# STM32H7B0xxQ register map
File version: 1.0
Registers are 32-bit, read-write, reset 0x0 unless marked. A register's access mark holds for its fields unless they carry their own. Offsets are from the block's base; [hi:lo] are bit positions; {n}, {i} and the like mark numbered series; 'fields as' and 'values as' point back to an identical list.

## OTFDEC1
Base 0x5200B800
Same registers: OTFDEC2 0x5200BC00
0x00 CR
  [0] ENC — Encryption mode bit
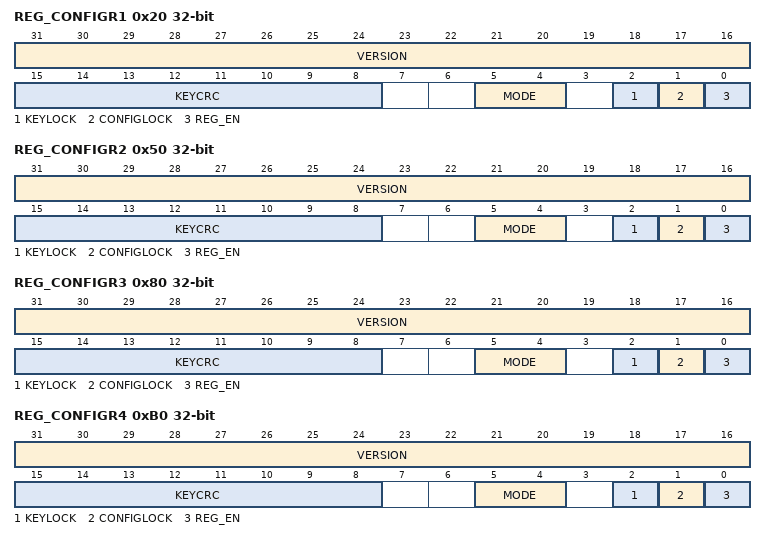
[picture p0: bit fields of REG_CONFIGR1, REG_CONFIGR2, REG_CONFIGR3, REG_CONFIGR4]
0x20 REG_CONFIGR1
  [31:16] VERSION — Region firmware version
  [15:8] KEYCRC — Region key 8-bit CRC
  [5:4] MODE — Region operating mode
  [2] KEYLOCK — Region key lock
  [1] CONFIGLOCK — Region config lock
  [0] REG_EN — Region on-the-fly decryption enable
0x24 REG_START_ADDR1
  [31:0] REG_START_ADDR — Region AHB start address
0x28 REG_END_ADDR1
  [31:0] REG_END_ADDR — Region AHB end address
0x2C REG_NONCER01
  [31:0] REG_NONCER0 — Region Nonce Register (LSB nonce[31:0])
0x30 REG_NONCER1
  [31:0] REG_NONCER1 — Region Nonce Register (MSB nonce[63:32])
{0x4+0x30*i} REG_KEYR{i:02} (i=1..4)
  [31:0] REG_KEYR0 — Region Key Register (LSB key[31:0])
{0x4+0x34*i} REG_KEYR{i} (i=1..3)
  [31:0] REG_KEYR{i} — Region Key Register (key[{32i+31}:{32i}])
0x3C REG_KEYR21
  [31:0] REG_KEYR2 — Region Key Register (key[95:64])
0x40 REG_KEYR31
  [31:0] REG_KEYR3 — Region Key Register (key[127:96])
0x50 REG_CONFIGR2
  fields as REG_CONFIGR1
0x54 REG_START_ADDR2
  [31:0] REG_START_ADDR — Region AHB start address
0x58 REG_END_ADDR2
  [31:0] REG_END_ADDR — Region AHB end address
0x5C REG_NONCER02
  [31:0] REG_NONCER0 — Region Nonce Register (LSB nonce[31:0])
0x60 REG_NONCER12
  [31:0] REG_NONCER1 — Region Nonce Register (MSB nonce[63:32])
0x68 REG_KEYR12
  [31:0] REG_KEYR1 — Region Key Register (key[63:32])
0x70 REG_KEYR32
  [31:0] REG_KEYR3 — Region Key Register (key[127:96])
0x80 REG_CONFIGR3
  fields as REG_CONFIGR1
0x84 REG_START_ADDR3
  [31:0] REG_START_ADDR — Region AHB start address
0x88 REG_END_ADDR3
  [31:0] REG_END_ADDR — Region AHB end address
0x8C REG_NONCER03
  [31:0] REG_NONCER0 — Region Nonce Register (LSB nonce[31:0])
0x90 REG_NONCER13
  [31:0] REG_NONCER1 — Region Nonce Register (MSB nonce[63:32])
0x98 REG_KEYR13
  [31:0] REG_KEYR1 — Region Key Register (key[63:32])
0x9C REG_KEYR23
  [31:0] REG_KEYR2 — Region Key Register (key[95:64])
0xB0 REG_CONFIGR4
  fields as REG_CONFIGR1
0xB4 REG_START_ADDR4
  [31:0] REG_START_ADDR — Region AHB start address
0xB8 REG_END_ADDR4
  [31:0] REG_END_ADDR — Region AHB end address
0xBC REG_NONCER04
  [31:0] REG_NONCER0 — Region Nonce Register (LSB nonce[31:0])
0xC0 REG_NONCER14
  [31:0] REG_NONCER1 — Region Nonce Register (MSB nonce[63:32])
0xC8 REG_KEYR14
  [31:0] REG_KEYR1 — Region Key Register (key[63:32])
0xCC REG_KEYR24
  [31:0] REG_KEYR2 — Region Key Register (key[95:64])
0xD0 REG_KEYR34
  [31:0] REG_KEYR3 — Region Key Register (key[127:96])
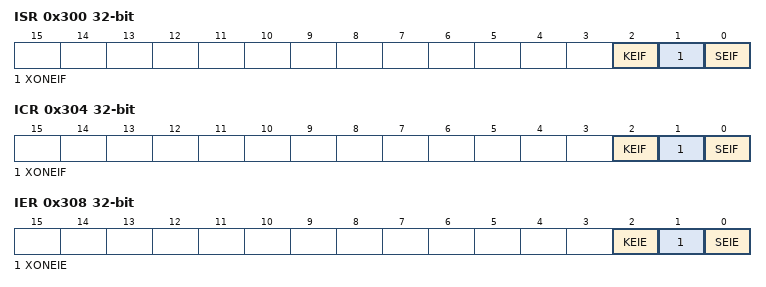
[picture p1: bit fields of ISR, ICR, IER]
0x300 ISR
  [2] KEIF — Key Error Interrupt Flag status bit before enable (mask)
  [1] XONEIF — Execute-only Error Interrupt Flag status bit before enable (mask)
  [0] SEIF — Security Error Interrupt Flag status bit before enable (mask)
0x304 ICR
  [2] KEIF — Key Error Interrupt Flag clear bit
  [1] XONEIF — Execute-only Error Interrupt Flag clear bit
  [0] SEIF — Security Error Interrupt Flag clear bit
0x308 IER
  [2] KEIE
  [1] XONEIE — Execute-only Error Interrupt Enable bit
  [0] SEIE — Security Error Interrupt Enable bit
0x3EC HWCFGR2
0x3F0 HWCFGR1
0x3F4 VERR
0x3F8 IPIDR
0x3FC SIDR

## GFXMMU — GFXMMU registers
Base 0x5200C000
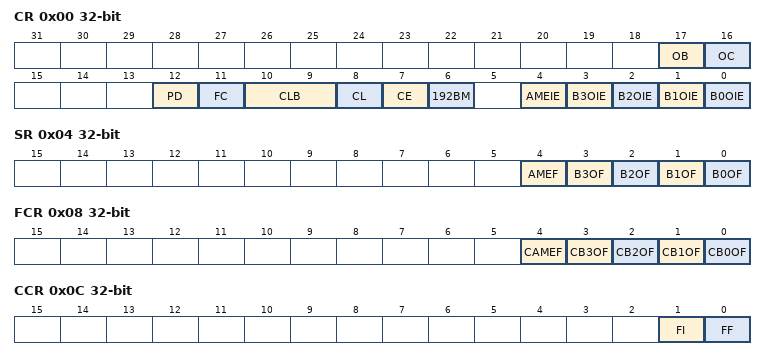
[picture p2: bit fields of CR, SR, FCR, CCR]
0x00 CR — GFXMMU configuration register
  [17] OB — Outer Bufferability
  [16] OC — Outer Cachability
  [12] PD — Prefetch Disable
  [11] FC — Force Caching
  [10:9] CLB — CLB[1:0]: Cache Lock Buffer
  [8] CL — Cache Lock
  [7] CE — Cache Enable
  [6] 192BM — 192 block mode
  [4] AMEIE — AHB master error interrupt enable
  [n] B{n}OIE (n=0..3) — Buffer {n} overflow interrupt enable
0x04 SR — GFXMMU status register
  [4] AMEF — AHB master error flag
  [n] B{n}OF (n=0..3) — Buffer {n} overflow flag
0x08 FCR — GFXMMU flag clear register
  [4] CAMEF — Clear AHB master error flag
  [n] CB{n}OF (n=0..3) — Clear buffer {n} overflow flag
0x0C CCR — GFXMMU Cache Control Register
  [1] FI — Clear buffer 1 overflow flag
  [0] FF — Clear buffer 0 overflow flag
0x10 DVR — GFXMMU default value register
  [31:0] DV — DV[31:0] bits (Default value)
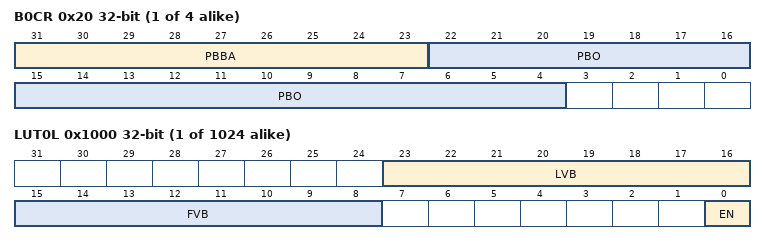
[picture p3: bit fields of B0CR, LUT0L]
{0x20+4i} B{i}CR (i=0..3) — GFXMMU buffer {i} configuration register
  [31:23] PBBA — PBBA[31:23] bits (Physical buffer base address)
  [22:4] PBO — PB0[22:4] bits (Physical buffer offset)
{0x1000+8i} LUT{i}L (i=0..1023) — GFXMMU LUT registers
  [23:16] LVB — LVB[7:0] bits (Last visible block)
  [15:8] FVB — FVB[7:0] bits (First visible block)
  [0] EN — Enable
{0x1004+8i} LUT{i}H (i=0..1023) — GFXMMU LUT registers
  [21:4] LO — LO[21:4] bits (Line offset)
